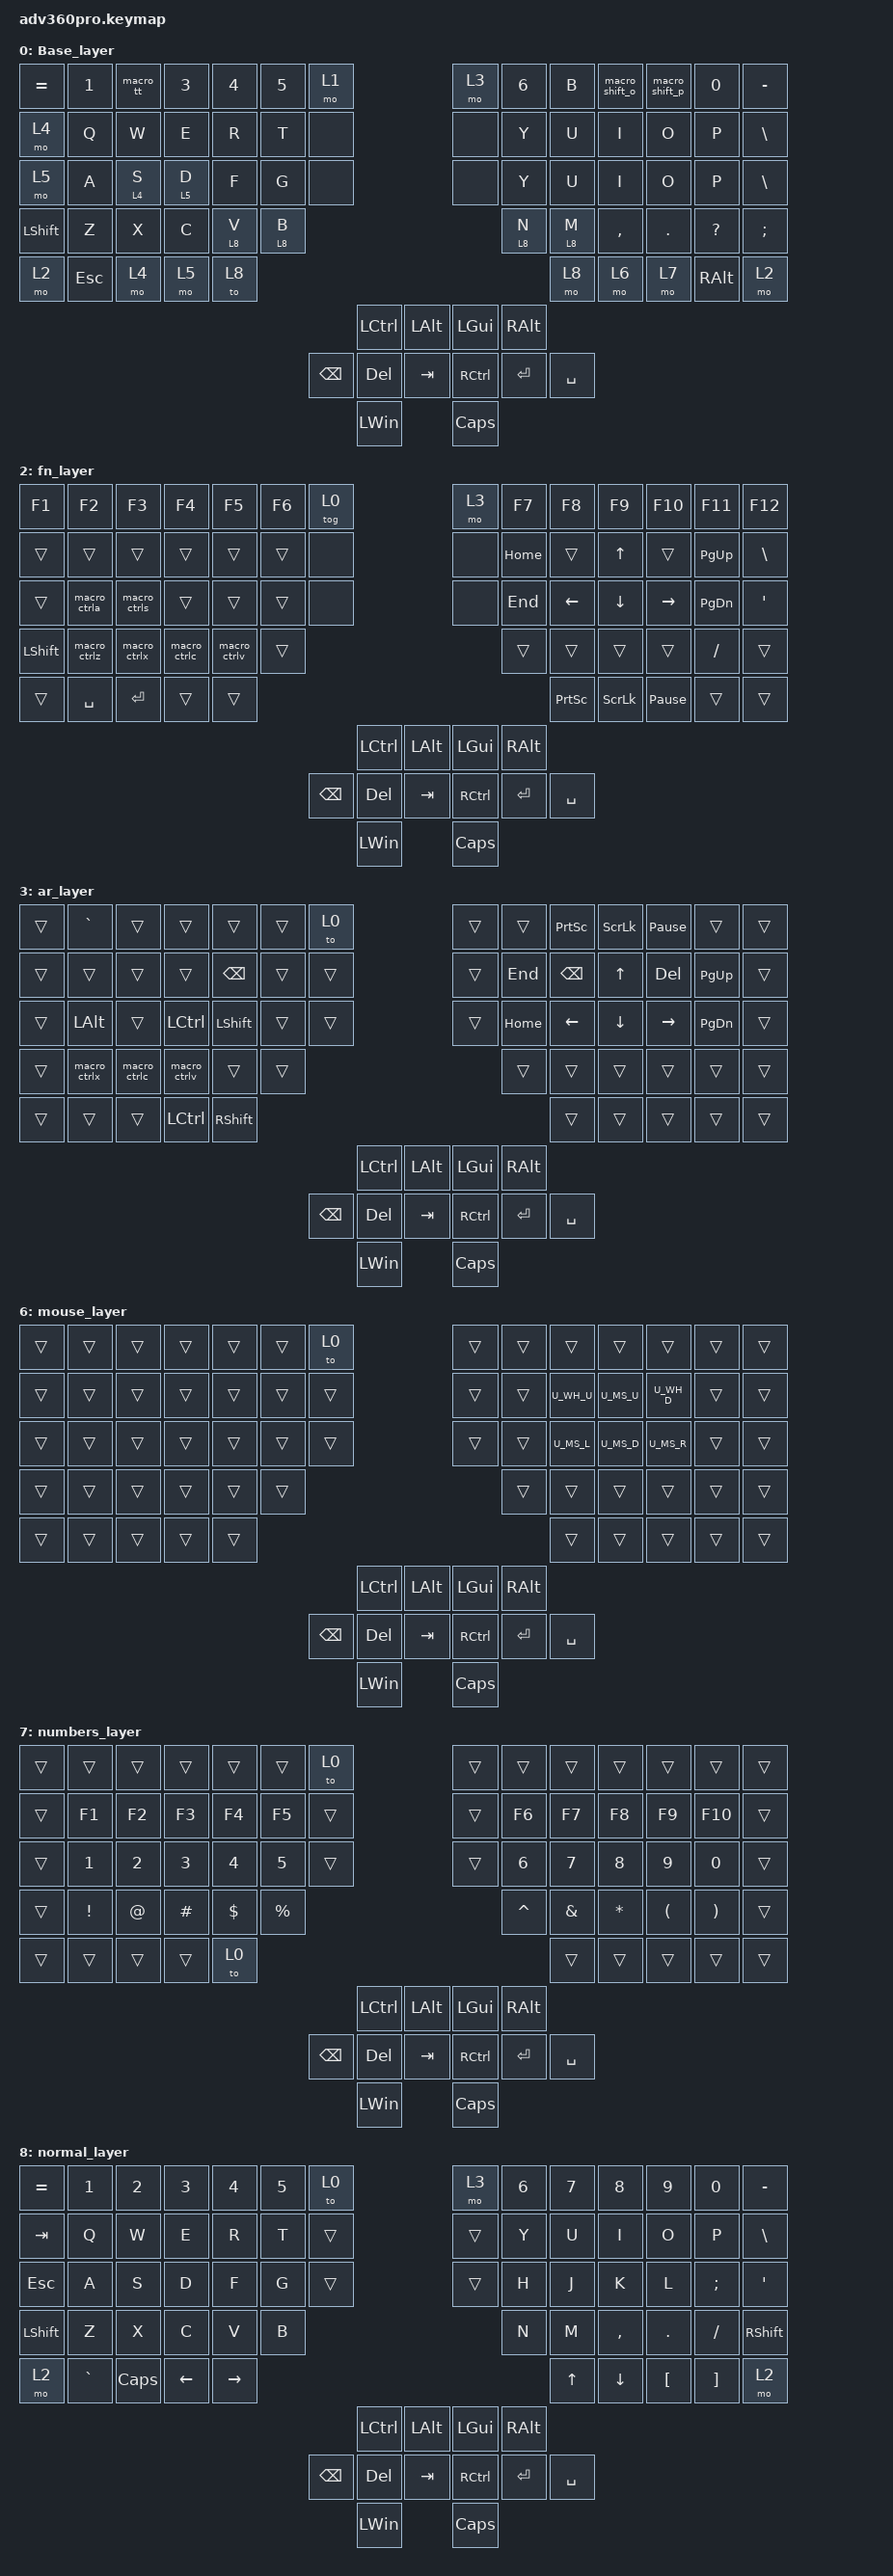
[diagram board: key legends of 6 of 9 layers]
#include <behaviors.dtsi>
#include <dt-bindings/zmk/keys.h>
#include <dt-bindings/zmk/bt.h>
#include <dt-bindings/zmk/outputs.h>
#include <dt-bindings/zmk/rgb.h>
#include <dt-bindings/zmk/backlight.h>
#include "adv360pro_keypos.h"
#include "zmk_helper.h"
/* definitions for mouse layer */
#include "mouse.h"

#define ___ &trans

/* Layer references  */
#define Base 0
#define keypad 1
#define fn 2
#define mod 3
#define ar 4
#define s1 5
#define s2 6
#define mouse 7
#define numbers 8
#define Normal 9


/* Global settings */
#include "general.h"

/* Home row mods */
#include "homerow_mods.h"

/* Macros and shortcuts */
#include "custom_behaviors.h"

/ {
    /* remove unused keys from layout and move thumb cluster to bottom */
    chosen {
        zmk,matrix_transform = &urobs_transform;
    };

    keymap {
        compatible = "zmk,keymap";

// base 1
        Base_layer {
            bindings = <
          &kp EQUAL   &kp N1  &macro_tt   &kp N3   &kp N4   &kp N5             &mo 1                                           &mo 3   &kp N6    &kp B  &macro_shift_o  &macro_shift_p        &kp N0      &kp MINUS
          &mo 4    &kp Q      &kp W    &kp E    &kp R    &kp T               &none                                             &none    &kp Y    &kp U           &kp I           &kp O         &kp P       &kp BSLH
          &mo 5    &kp A    &lt 4 S  &lt 5 D    &kp F    &kp G               &none                                             &none    &kp Y    &kp U           &kp I           &kp O         &kp P       &kp BSLH
          &kp LEFT_SHIFT    &kp Z      &kp X    &kp C  &lt 8 V  &lt 8 B                                                                    &lt 8 N  &lt 8 M      &kp COMMA         &kp DOT  &kp QUESTION  &kp SEMICOLON
          &mo 2  &kp ESC      &mo 4    &mo 5    &to 8                                                                                         &mo 8           &mo 6           &mo 7      &kp RALT          &mo 2

                                                                          &kp LCTRL      &kp LALT                 &kp LGUI   &kp RALT 
                                                                  &kp BSPC    &kp DEL     &kp TAB                  &kp RCTRL  &kp ENTER  &kp SPACE
                                                                                   &kp LEFT_WIN                   &kp CAPS


            >;
        };

// KEYPAD 1
    keypad_layer {
            bindings = <
             &kp EQUAL     &kp N1    &kp N2    &kp N3     &kp N4  &kp N5               &to 0                                                                 &mo 3  &kp N6  &kp KP_NUM  &kp KP_EQUAL  &kp KP_DIVIDE  &kp KP_MULTIPLY  &kp MINUS
   &kp TAB      &kp Q     &kp W     &kp E      &kp R   &kp T               &none                                                                 &none   &kp Y   &kp KP_N7     &kp KP_N8      &kp KP_N9     &kp KP_MINUS   &kp BSLH
   &kp ESC      &kp A     &kp S     &kp D      &kp F   &kp G               &none                                                                 &none   &kp H   &kp KP_N4     &kp KP_N5      &kp KP_N6      &kp KP_PLUS    &kp SQT
 &kp LSHFT      &kp Z     &kp X     &kp C      &kp V   &kp B                                                                                     &kp N   &kp KP_N1     &kp KP_N2      &kp KP_N3     &kp KP_ENTER  &kp RSHFT
     &mo 2  &kp GRAVE  &kp CAPS  &kp LEFT  &kp RIGHT                                                                                             &kp UP      &kp DOWN     &kp KP_DOT         &kp RBKT      &mo 2
                                                                                   &kp HOME                  &kp PG_UP
                                                                            &kp BSPC    &kp DEL   &kp    &kp ENTER  &kp KP_N0 
                                                                                       END                  &kp PG_DN
            >;
        };

// FN 2
        fn_layer {
            bindings = <
    &kp F1        &kp F2        &kp F3        &kp F4        &kp F5  &kp F6            &tog 0                                                   &mo 3    &kp F7           &kp F8          &kp F9          &kp F10    &kp F11   &kp F12
    &trans        &trans        &trans        &trans        &trans  &trans             &none                                                   &none    &kp HOME         &trans          &kp UP           &trans    &kp PG_UP  &kp BSLH
    &trans  &macro_ctrla  &macro_ctrls        &trans        &trans  &trans             &none                                                   &none    &kp END          &kp LEFT        &kp DOWN         &kp RIGHT &kp PG_DN  &kp SQT
 &kp LSHFT  &macro_ctrlz  &macro_ctrlx  &macro_ctrlc  &macro_ctrlv  &trans                                                                              &trans          &trans          &trans           &trans   &kp SLASH    &trans
    &trans     &kp SPACE     &kp ENTER        &trans        &trans                                                                                        &kp PRINTSCREEN  &kp SCROLLLOCK  &kp PAUSE_BREAK     &trans   &trans
                                                                          &kp LCTRL      &kp LALT                 &kp LGUI   &kp RALT 
                                                                  &kp BSPC    &kp DEL     &kp TAB                  &kp RCTRL  &kp ENTER  &kp SPACE
                                                                                   &kp LEFT_WIN                   &kp CAPS

            >;
        };


 //  MOD 3
        mod_layer {
      &none  &bt_SEL 0  &bt_SEL 1  &bt_SEL 2  &bt_SEL 3  &bt_SEL 4                  &none                                                                          &trans   &none       &none       &none   &none   &none   &none
  &none         &none         &none         &none         &none         &none            &bootloader                                                                     &bootloader   &none       &none       &none   &none   &none   &none
  &none         &none         &none         &none         &none         &none                  &none                                                                          &none    &none          &BT_CLR       &none  &rgb_ug RGB_MEFS_CMD 5   &none       &none 
  &none         &none         &none         &none    &macro_ver         &none                                                                                                                 &none       &none       &none   &none   &none   &none
  &none         &none         &none         &none         &none                                                                                                          &bl BL_TOG         &rgb_ug RGB_TOG          &bl BL_INC  &bl BL_DEC   &none   &none   &none
                                                                          &kp LCTRL      &kp LALT                 &kp LGUI   &kp RALT 
                                                                  &kp BSPC    &kp DEL     &kp TAB                  &kp RCTRL  &kp ENTER  &kp SPACE
                                                                                   &kp LEFT_WIN                   &kp CAPS
            >;
        };
 // arrows4
       ar_layer {
            bindings = <
    &trans     &kp GRAVE  &trans        &trans        &trans  &trans                    &to 0                                                        &trans    &trans  &kp PRINTSCREEN  &kp SCROLLLOCK  &kp PAUSE_BREAK     &trans  &trans
    &trans     &trans     &trans        &trans        &kp BSPC  &trans                   &trans                                                        &trans    &kp END    &kp BACKSPACE          &kp UP          &kp DEL  &kp PG_UP  &trans
    &trans     &kp LALT   &trans        &kp LCTRL     &kp LSHFT &trans                   &trans                                                        &trans    &kp HOME   &kp LEFT               &kp DOWN        &kp RIGHT  &kp PG_DN  &trans
    &trans     &macro_ctrlx  &macro_ctrlc  &macro_ctrlv  &trans  &trans                                                                                          &trans     &trans                 &trans          &trans     &trans    &trans
    &trans     &trans     &trans        &kp LCTRL     &kp RSHFT                                                                                                      &trans          &trans           &trans     &trans  &trans
                                                                          &kp LCTRL      &kp LALT                 &kp LGUI   &kp RALT 
                                                                  &kp BSPC    &kp DEL     &kp TAB                  &kp RCTRL  &kp ENTER  &kp SPACE
                                                                                   &kp LEFT_WIN                   &kp CAPS
            >;
        };

// layer_symbols_left 5
        s1_layer {
          bindings = <
    &trans  &trans  &trans  &trans    &trans  &trans             &to 0                                                  &trans         &trans                &trans                 &trans          &trans          &trans  &kp GRAVE
    &trans  &trans  &trans  &trans    &trans  &trans            &trans                                                  &trans      &kp EQUAL  &kp LEFT_PARENTHESIS  &kp RIGHT_PARENTHESIS  &macro_shift_o  &macro_shift_p   &kp BSLH
    &kp LSHFT  &trans  &trans  &trans    &trans  &trans            &trans                                               &trans      &kp SEMICOLON          &kp QUESTION               &kp EXCL         &kp SQT         &kp DQT    &kp DQT
    &trans  &trans  &trans  &trans    &kp RALT  &trans                                                                                  &kp SLASH             &kp MINUS                &kp DQT     &macro_dots    &kp QUESTION  &kp COLON
    &trans  &trans  &trans  &trans    &trans                                                                                               &trans                   &trans                 &trans          &trans          &trans     &trans
                                                                          &kp LCTRL      &kp LALT                 &kp LGUI   &kp RALT 
                                                                  &kp BSPC    &kp DEL     &kp TAB                  &kp RCTRL  &kp ENTER  &kp SPACE
                                                                                   &kp LEFT_WIN                   &kp CAPS

            >;
        };
// layer_symbols_RIGHT 6
        s2_layer {
          bindings = <
    &kp TILDE     &macro_shift1     &macro_shift_2         &macro_shift3         &macro_shift_4  &macro_shift_5             &to 0                                                                     &trans          &trans           &trans  &trans  &trans  &trans  &trans
    &trans        &macro_shift_q     &macro_shift_w        &macro_shift_e         &macro_shift_r  &macro_shift_t            &trans                                                                     &trans          &trans           &trans  &trans  &trans  &trans  &trans
    &trans        &kp LEFT_BRACKET   &kp RIGHT_BRACKET     &kp LEFT_PARENTHESIS   &kp RIGHT_PARENTHESIS          &trans            &trans                                                                     &trans          &trans           &trans  &trans          &trans  &trans  &trans
    &trans        &trans             &trans                &trans                 &trans          &trans                                                                                                     &macro_alt_cap    &macro_ctrl_cap  &trans  &trans  &trans  &trans
    &trans        &trans             &trans                &trans                 &trans                            &trans                                                                            &trans  &macro_lang_change  &kp RIGHT_ALT           &trans  &trans
                                                                          &kp LCTRL      &kp LALT                 &kp LGUI   &kp RALT 
                                                                  &kp BSPC    &kp DEL     &kp TAB                  &kp RCTRL  &kp ENTER  &kp SPACE
                                                                                   &kp LEFT_WIN                   &kp CAPS
            >;
        };

// layer_mouse 7
        mouse_layer {
            bindings = <
    &trans  &trans  &trans  &trans  &trans  &trans             &to 0                                                  &trans  &trans  &trans  &trans  &trans  &trans  &trans
    &trans  &trans  &trans  &trans  &trans  &trans            &trans                                                  &trans  &trans  &U_WH_U  &U_MS_U  &U_WH_D  &trans  &trans
    &trans  &trans  &trans  &trans  &trans  &trans            &trans                                                  &trans  &trans  &U_MS_L  &U_MS_D  &U_MS_R  &trans  &trans  
    &trans  &trans  &trans  &trans  &trans  &trans                                                                            &trans  &trans  &trans  &trans  &trans  &trans
    &trans  &trans  &trans  &trans  &trans                                                                                            &trans  &trans  &trans  &trans  &trans
                                                                          &kp LCTRL      &kp LALT                 &kp LGUI   &kp RALT 
                                                                  &kp BSPC    &kp DEL     &kp TAB                  &kp RCTRL  &kp ENTER  &kp SPACE
                                                                                   &kp LEFT_WIN                   &kp CAPS
            >;
        };

// layer_numbers 8
        numbers_layer {
            bindings = <
    &trans    &trans  &trans        &trans        &trans        &trans             &to 0                                                  &trans     &trans         &trans        &trans                &trans                 &trans  &trans
    &trans    &kp F1  &kp F2        &kp F3        &kp F4        &kp F5            &trans                                                  &trans     &kp F6         &kp F7        &kp F8                &kp F9                &kp F10  &trans
    &trans    &kp N1  &kp N2        &kp NUMBER_3  &kp NUMBER_4  &kp NUMBER_5      &trans                                                  &trans     &kp N6         &kp N7        &kp N8                &kp N9                 &kp N0  &trans
    &trans    &kp EXCL  &kp AT      &kp HASH      &kp DLLR     &kp PRCNT                                                                             &kp CARET  &kp AMPERSAND  &kp ASTERISK  &kp LEFT_PARENTHESIS  &kp RIGHT_PARENTHESIS  &trans
    &trans    &trans  &trans        &trans         &to 0                                                                                                            &trans            &trans           &trans                 &trans  &trans
                                                                          &kp LCTRL      &kp LALT                 &kp LGUI   &kp RALT 
                                                                  &kp BSPC    &kp DEL     &kp TAB                  &kp RCTRL  &kp ENTER  &kp SPACE
                                                                                   &kp LEFT_WIN                   &kp CAPS
            >;
        };
// NORMAL_KEY 9
        normal_layer {
            bindings = <
    &kp EQUAL     &kp N1    &kp N2    &kp N3     &kp N4  &kp N5               &to 0                                                                     &mo 3  &kp N6  &kp N7     &kp N8            &kp N9             &kp N0      &kp MINUS
    &kp TAB      &kp Q     &kp W     &kp E      &kp R   &kp T              &trans                                                                    &trans   &kp Y   &kp U      &kp I             &kp O              &kp P  &kp BACKSLASH
    &kp ESC      &kp A     &kp S     &kp D      &kp F   &kp G              &trans                                                                    &trans   &kp H   &kp J      &kp K             &kp L      &kp SEMICOLON        &kp SQT
    &kp LSHIFT      &kp Z     &kp X     &kp C      &kp V   &kp B                                                                                               &kp N   &kp M  &kp COMMA           &kp DOT          &kp SLASH      &kp RSHFT
    &mo 2  &kp GRAVE  &kp CAPS  &kp LEFT  &kp RIGHT                                                                                                                   &kp UP   &kp DOWN  &kp LEFT_BRACKET  &kp RIGHT_BRACKET          &mo 2
                                                                          &kp LCTRL      &kp LALT                 &kp LGUI   &kp RALT 
                                                                  &kp BSPC    &kp DEL     &kp TAB                  &kp RCTRL  &kp ENTER  &kp SPACE
                                                                                   &kp LEFT_WIN                   &kp CAPS

            >;
        };


    };
};

